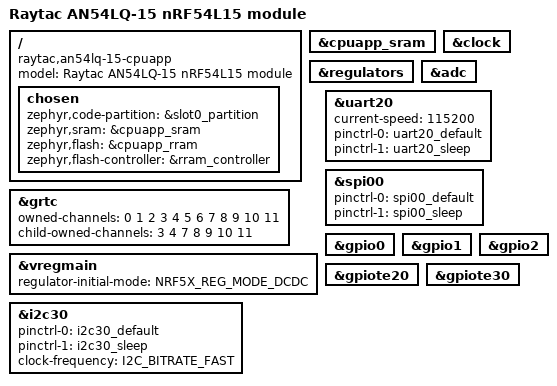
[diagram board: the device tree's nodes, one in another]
/*
 * Copyright (c) 2025 SlimeVR contributors
 * SPDX-License-Identifier: MIT
 */

/dts-v1/;
#include <nordic/nrf54l15_cpuapp.dtsi>
#include "an54lq-15-pinctrl.dtsi"

/ {
	model = "Raytac AN54LQ-15 nRF54L15 module";
	compatible = "raytac,an54lq-15-cpuapp";

	chosen {
		zephyr,code-partition = &slot0_partition;
		zephyr,sram = &cpuapp_sram;
		zephyr,flash = &cpuapp_rram;
		zephyr,flash-controller = &rram_controller;
	};
};

&grtc {
	owned-channels = <0 1 2 3 4 5 6 7 8 9 10 11>;
	/* Channels 7-11 reserved for Zero Latency IRQs, 3-4 for FLPR */
	child-owned-channels = <3 4 7 8 9 10 11>;
	status = "okay";
};

&cpuapp_sram {
	status = "okay";
};

&clock {
	status = "okay";
};

/* Switch internal regulator to DCDC mode for better performance */
&regulators {
	status = "okay";
};

&vregmain {
	status = "okay";
	regulator-initial-mode = <NRF5X_REG_MODE_DCDC>;
};

&adc {
	status = "okay";
	#address-cells = <1>;
	#size-cells = <0>;
};

&uart20 {
	status = "okay";
	current-speed = <115200>;
	pinctrl-0 = <&uart20_default>;
	pinctrl-1 = <&uart20_sleep>;
	pinctrl-names = "default", "sleep";
};

&spi00 {
	status = "okay";
	pinctrl-0 = <&spi00_default>;
	pinctrl-1 = <&spi00_sleep>;
	pinctrl-names = "default", "sleep";
};

&i2c30 {
	status = "okay";
	pinctrl-0 = <&i2c30_default>;
	pinctrl-1 = <&i2c30_sleep>;
	pinctrl-names = "default", "sleep";
	clock-frequency = <I2C_BITRATE_FAST>;
};

&gpio0 {
	status = "okay";
};

&gpio1 {
	status = "okay";
};

&gpio2 {
	status = "okay";
};

&gpiote20 {
	status = "okay";
};

&gpiote30 {
	status = "okay";
};

#include <nordic/nrf54l15_partition.dtsi>
